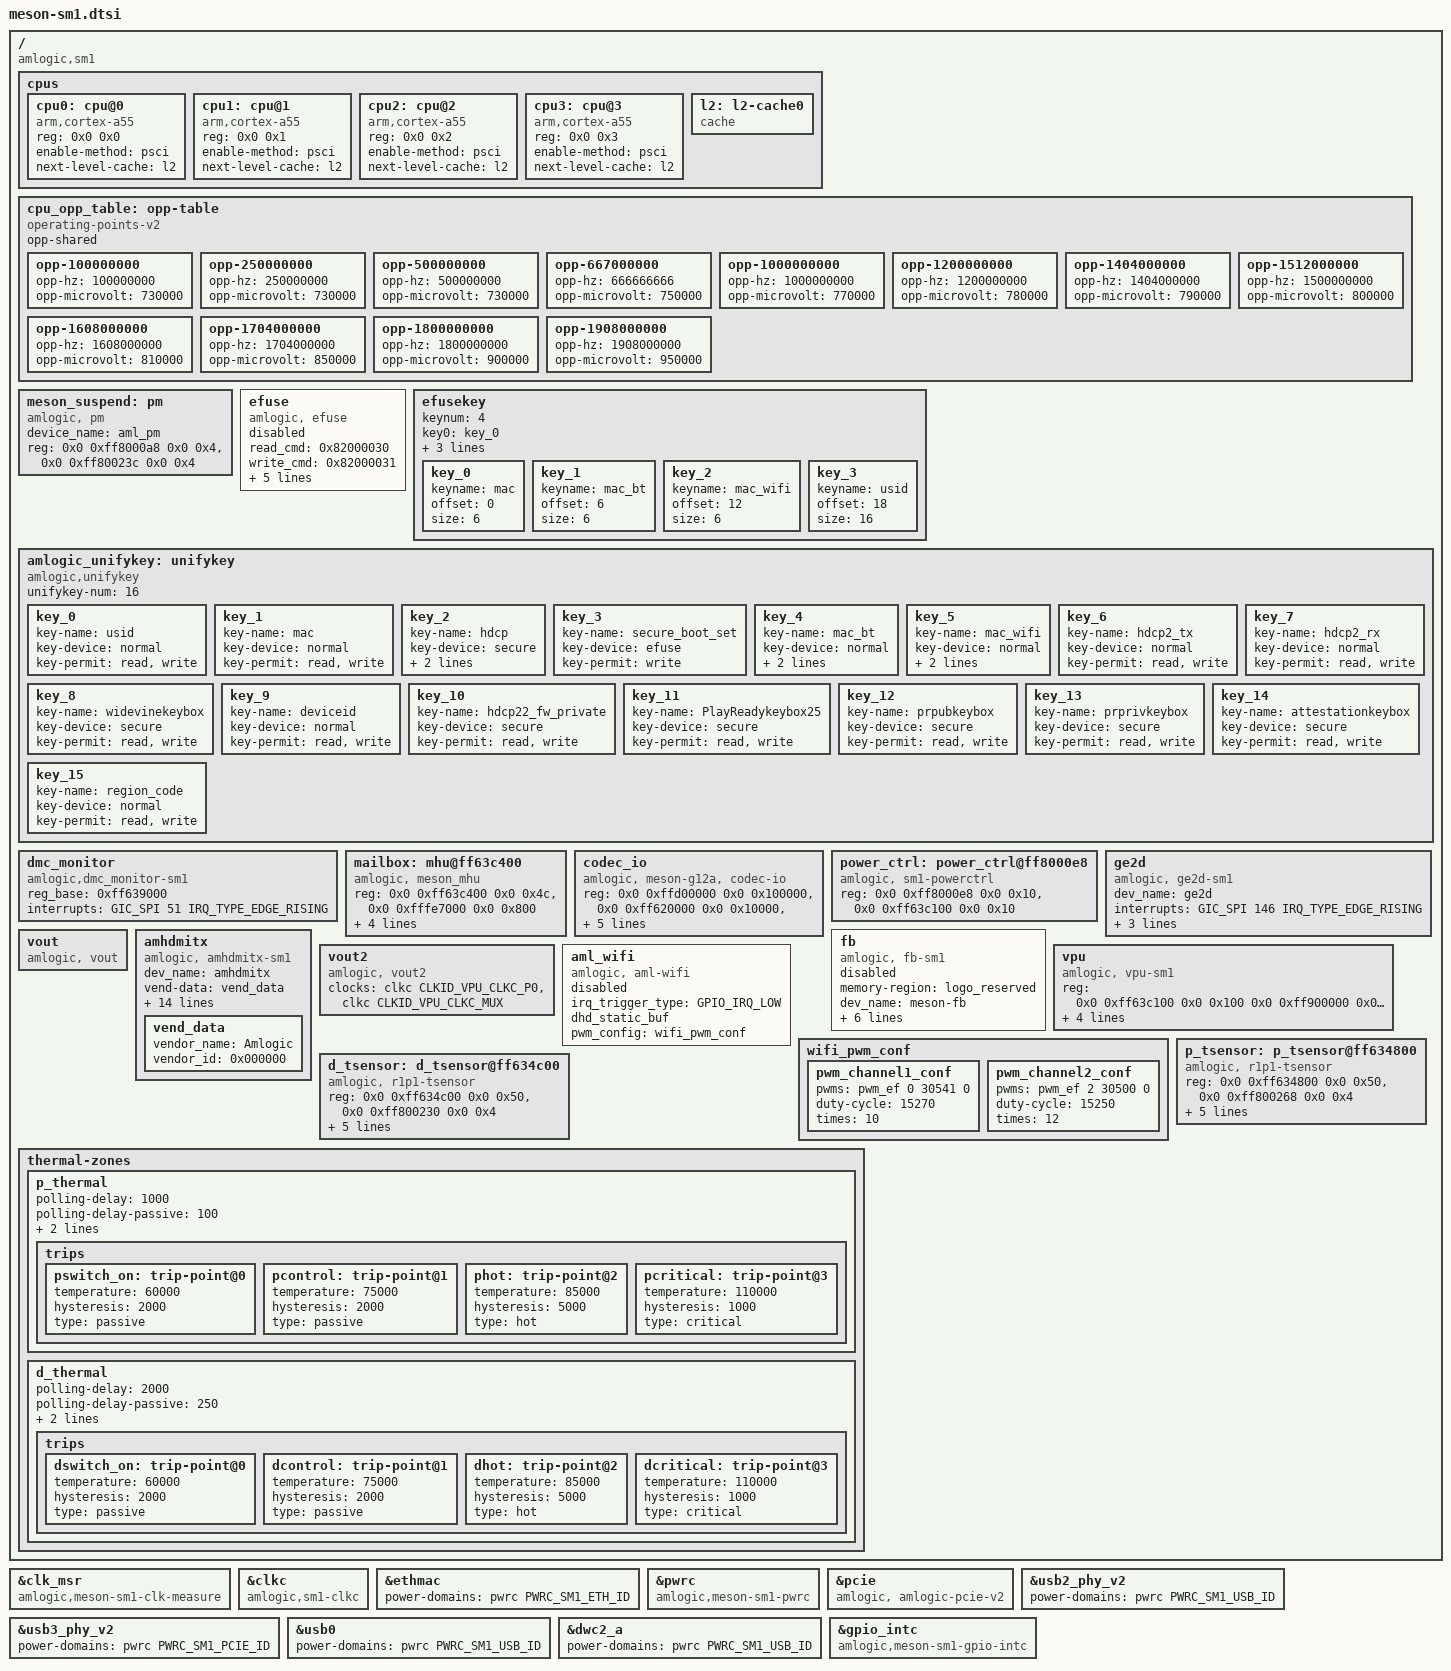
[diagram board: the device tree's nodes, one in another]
// SPDX-License-Identifier: (GPL-2.0+ OR MIT)
/*
 * Copyright (c) 2019 BayLibre, SAS
 * Author: Neil Armstrong <narmstrong@baylibre.com>
 */

#include "meson-g12-common.dtsi"
#include <dt-bindings/power/meson-sm1-power.h>

/ {
	compatible = "amlogic,sm1";

	cpus {
		#address-cells = <0x2>;
		#size-cells = <0x0>;

		cpu0: cpu@0 {
			device_type = "cpu";
			compatible = "arm,cortex-a55";
			reg = <0x0 0x0>;
			enable-method = "psci";
			next-level-cache = <&l2>;
		};

		cpu1: cpu@1 {
			device_type = "cpu";
			compatible = "arm,cortex-a55";
			reg = <0x0 0x1>;
			enable-method = "psci";
			next-level-cache = <&l2>;
		};

		cpu2: cpu@2 {
			device_type = "cpu";
			compatible = "arm,cortex-a55";
			reg = <0x0 0x2>;
			enable-method = "psci";
			next-level-cache = <&l2>;
		};

		cpu3: cpu@3 {
			device_type = "cpu";
			compatible = "arm,cortex-a55";
			reg = <0x0 0x3>;
			enable-method = "psci";
			next-level-cache = <&l2>;
		};

		l2: l2-cache0 {
			compatible = "cache";
		};
	};

	cpu_opp_table: opp-table {
		compatible = "operating-points-v2";
		opp-shared;

		opp-100000000 {
			opp-hz = /bits/ 64 <100000000>;
			opp-microvolt = <730000>;
		};

		opp-250000000 {
			opp-hz = /bits/ 64 <250000000>;
			opp-microvolt = <730000>;
		};

		opp-500000000 {
			opp-hz = /bits/ 64 <500000000>;
			opp-microvolt = <730000>;
		};

		opp-667000000 {
			opp-hz = /bits/ 64 <666666666>;
			opp-microvolt = <750000>;
		};

		opp-1000000000 {
			opp-hz = /bits/ 64 <1000000000>;
			opp-microvolt = <770000>;
		};

		opp-1200000000 {
			opp-hz = /bits/ 64 <1200000000>;
			opp-microvolt = <780000>;
		};

		opp-1404000000 {
			opp-hz = /bits/ 64 <1404000000>;
			opp-microvolt = <790000>;
		};

		opp-1512000000 {
			opp-hz = /bits/ 64 <1500000000>;
			opp-microvolt = <800000>;
		};

		opp-1608000000 {
			opp-hz = /bits/ 64 <1608000000>;
			opp-microvolt = <810000>;
		};

		opp-1704000000 {
			opp-hz = /bits/ 64 <1704000000>;
			opp-microvolt = <850000>;
		};

		opp-1800000000 {
			opp-hz = /bits/ 64 <1800000000>;
			opp-microvolt = <900000>;
		};

		opp-1908000000 {
			opp-hz = /bits/ 64 <1908000000>;
			opp-microvolt = <950000>;
		};
	};

	meson_suspend:pm {
		compatible = "amlogic, pm";
		status = "okay";
		device_name = "aml_pm";
		reg = <0x0 0xff8000a8 0x0 0x4>,
			<0x0 0xff80023c 0x0 0x4>;
	};

	efuse: efuse {
		compatible = "amlogic, efuse";
		read_cmd = <0x82000030>;
		write_cmd = <0x82000031>;
		get_max_cmd = <0x82000033>;
		mem_in_base_cmd = <0x82000020>;
		mem_out_base_cmd = <0x82000021>;
		key = <&efusekey>;
		clocks = <&clkc CLKID_EFUSE>;
		clock-names = "efuse_clk";
		status = "disabled";
	};

	efusekey: efusekey {
		keynum = <4>;
		key0 = <&key_0>;
		key1 = <&key_1>;
		key2 = <&key_2>;
		key3 = <&key_3>;

		key_0: key_0 {
			keyname = "mac";
			offset = <0>;
			size = <6>;
		};
		key_1: key_1 {
			keyname = "mac_bt";
			offset = <6>;
			size = <6>;
		};
		key_2: key_2 {
			keyname = "mac_wifi";
			offset = <12>;
			size = <6>;
		};
		key_3: key_3 {
			keyname = "usid";
			offset = <18>;
			size = <16>;
		};
	};

	amlogic_unifykey: unifykey{
		compatible = "amlogic,unifykey";
		status = "okay";

		unifykey-num = <16>;

		key_0{
			key-name = "usid";
			key-device = "normal";
			key-permit = "read","write";
		};
		key_1{
			key-name = "mac";
			key-device = "normal";
			key-permit = "read","write";
		};
		key_2{
			key-name = "hdcp";
			key-device = "secure";
			key-type = "sha1";
			key-permit = "read","write";
		};
		key_3{
			key-name = "secure_boot_set";
			key-device = "efuse";
			key-permit = "write";
		};
		key_4{
			key-name = "mac_bt";
			key-device = "normal";
			key-permit = "read","write";
			key-type  = "mac";
		};
		key_5{
			key-name = "mac_wifi";
			key-device = "normal";
			key-permit = "read","write";
			key-type = "mac";
		};
		key_6{
			key-name = "hdcp2_tx";
			key-device = "normal";
			key-permit = "read","write";
		};
		key_7{
			key-name = "hdcp2_rx";
			key-device = "normal";
			key-permit = "read","write";
		};
		key_8{
			key-name = "widevinekeybox";
			key-device = "secure";
			key-permit = "read","write";
		};
		key_9{
			key-name = "deviceid";
			key-device = "normal";
			key-permit = "read","write";
		};
		key_10{
			key-name = "hdcp22_fw_private";
			key-device = "secure";
			key-permit = "read","write";
		};
		key_11{
			key-name = "PlayReadykeybox25";
			key-device = "secure";
			key-permit = "read","write";
		};
		key_12{
			key-name = "prpubkeybox";// PlayReady
			key-device = "secure";
			key-permit = "read","write";
		};
		key_13{
			key-name = "prprivkeybox";// PlayReady
			key-device = "secure";
			key-permit = "read","write";
		};
		key_14{
			key-name = "attestationkeybox";// attestation key
			key-device = "secure";
			key-permit = "read","write";
		};
		key_15{
			key-name = "region_code";
			key-device = "normal";
			key-permit = "read","write";
		};
	};//End unifykey

	dmc_monitor {
		compatible = "amlogic,dmc_monitor-sm1";
		status = "okay";
		reg_base = <0xff639000>;
		interrupts = <GIC_SPI 51 IRQ_TYPE_EDGE_RISING>;
	};

	mailbox: mhu@ff63c400 {
		compatible = "amlogic, meson_mhu";
		reg = <0x0 0xff63c400 0x0 0x4c>,   /*MHU registers*/
			<0x0 0xfffe7000 0x0 0x800>;   /*Payload area*/
		interrupts = <GIC_SPI 209 IRQ_TYPE_EDGE_RISING>,   /*low isr*/
				<GIC_SPI 210 IRQ_TYPE_EDGE_RISING>; /*high isr*/
		#mbox-cells = <1>;
		mbox-names = "cpu_to_scp_low", "cpu_to_scp_high";
		mboxes = <&mailbox 0 &mailbox 1>;
	};

	codec_io: codec_io {
		compatible = "amlogic, meson-g12a, codec-io";
		status = "okay";
		#address-cells=<2>;
		#size-cells=<2>;
		ranges;
		reg =	<0x0 0xffd00000 0x0 0x100000>,
			<0x0 0xff620000 0x0 0x10000>,
			<0x0 0xff63c000 0x0 0x2000>,
			<0x0 0xff800000 0x0 0x10000>,
			<0x0 0xff900000 0x0 0x40000>,
			<0x0 0xff638000 0x0 0x2000>,
			<0x0 0xff630000 0x0 0x2000>;
		reg-names = "cbus",
			    "dosbus",
			    "hiubus",
			    "aobus",
			    "vcbus",
			    "dmcbus",
			    "efusebus";
	};
	power_ctrl: power_ctrl@ff8000e8 {
		compatible = "amlogic, sm1-powerctrl";
		reg = <0x0 0xff8000e8 0x0 0x10>,
		<0x0 0xff63c100 0x0 0x10>;
	};

	ge2d {
		compatible = "amlogic, ge2d-sm1";
		dev_name = "ge2d";
		status = "okay";
		interrupts = <GIC_SPI 146 IRQ_TYPE_EDGE_RISING>;
		interrupt-names = "ge2d";
		clocks = <&clkc CLKID_VAPB_SEL>,
			<&clkc CLKID_G2D>,
			<&clkc CLKID_VAPB>;
		clock-names = "clk_vapb_0",
			"clk_ge2d",
			"clk_ge2d_gate";
		reg = <0x0 0xff940000 0x0 0x10000>;
	};

	vout {
		compatible = "amlogic, vout";
		status = "okay";
	};

	fb: fb {
		compatible = "amlogic, fb-sm1";
		memory-region = <&logo_reserved>;
		dev_name = "meson-fb";
		status = "disable";
		interrupts = <GIC_SPI 3 IRQ_TYPE_EDGE_RISING
			GIC_SPI 56 IRQ_TYPE_EDGE_RISING
			GIC_SPI 89 IRQ_TYPE_EDGE_RISING>;
		interrupt-names = "viu-vsync", "viu2-vsync", "rdma";
		/* uboot logo,fb0/fb1 memory size,if afbcd fb0=0x01851000*/
		display_mode_default = "1080p60hz";
		scale_mode = <1>;
		/** 0:VPU free scale 1:OSD free scale 2:OSD super scale */
		display_size_default = <1920 1080 1920 2160 32>;
		/*1920*1080*4*3 = 0x17BB000*/
		clocks = <&clkc CLKID_VPU_CLKC_MUX>;
		clock-names = "vpu_clkc";
	};

	amhdmitx: amhdmitx{
		compatible = "amlogic, amhdmitx-sm1";
		dev_name = "amhdmitx";
		status = "okay";
		vend-data = <&vend_data>;
		pinctrl-names="default", "hdmitx_i2c";
		pinctrl-0=<&hdmitx_hpd_pins &hdmitx_ddc_pins>;
		pinctrl-1=<&hdmitx_hpd_gpio &i2c3_sda_h_pins>;
		clocks = <&clkc CLKID_VCLK2_ENCI
			&clkc CLKID_VCLK2_VENCI0
			&clkc CLKID_VCLK2_VENCI1
			&clkc CLKID_VAPB_SEL
			&clkc CLKID_VPU>;
		clock-names = "venci_top_gate",
			"venci_0_gate",
			"venci_1_gate",
			"hdmi_vapb_clk",
			"hdmi_vpu_clk";
		/* HPD, 57 + 32 = 89; CEC, 151 + 32 = 183*/
		interrupts = <GIC_SPI 57 IRQ_TYPE_EDGE_RISING>;
		interrupt-names = "hdmitx_hpd";
		/* 0:M8B 1:GXBB 2:GXTVBB 3:GXL 4:GXM
		 * 5:TXL 6:TXLX 7:AXG 8:GXLX 9:TXHD
		 * 10:G12A 11:G12B 12:SM1
		 */
		ic_type = <12>;
		reg =	<0x0 0xffd00000 0x0 0x100000>,
			<0x0 0xff900000 0x0 0x40000>,
			<0x0 0xff63c000 0x0 0x2000>,
			<0x0 0xff600000 0x0 0x8000>,
			<0x0 0xff608000 0x0 0x4000>,
			<0x0 0xffe01000 0x0 0x100>;
		reg-names = "cbus",
			    "vcbus",
			    "hiubus",
			    "hdmitxsec",
			    "hdmitx",
			    "esm";

		vend_data: vend_data{ /* Should modified by Customer */
			vendor_name = "Amlogic"; /* Max Chars: 8 */
			/* standards.ieee.org/develop/regauth/oui/oui.txt */
			vendor_id = <0x000000>;
		};
	};

	vout2 {
		compatible = "amlogic, vout2";
		status = "okay";
		clocks = <&clkc CLKID_VPU_CLKC_P0>,
			<&clkc CLKID_VPU_CLKC_MUX>;
		clock-names = "vpu_clkc0",
			"vpu_clkc";
	};
	vpu: vpu {
		compatible = "amlogic, vpu-sm1";
		status = "okay";
		reg =	<0x0 0xff63c100 0x0 0x100    /* hiu */
			0x0 0xff900000 0x0 0x50000 /* vcbus */
			0x0 0xffd01080 0x0 0x20    /* cbus */
			0x0 0xff8000e8 0x0 0x2>;   /* aobus */
		clocks = <&clkc CLKID_VAPB_SEL>,
			<&clkc CLKID_VPU_INTR>,
			<&clkc CLKID_VPU_0>,
			<&clkc CLKID_VPU_1>,
			<&clkc CLKID_VPU>;
		clock-names =	"vapb_clk",
				"vpu_intr_gate",
				"vpu_clk0",
				"vpu_clk1",
				"vpu_clk";
		clk_level = <7>;
		/* 0: 100.0M    1: 166.7M    2: 200.0M    3: 250.0M */
		/* 4: 333.3M    5: 400.0M    6: 500.0M    7: 666.7M */
	};

	aml_wifi: aml_wifi {
		compatible = "amlogic, aml-wifi";
		status = "disabled";
		irq_trigger_type = "GPIO_IRQ_LOW";
		dhd_static_buf; //if use bcm wifi, config dhd_static_buf
		//pinctrl-0 = <&pwm_e_pins>;
		//pinctrl-names = "default";
		pwm_config = <&wifi_pwm_conf>;
	};

	wifi_pwm_conf:wifi_pwm_conf{
		pwm_channel1_conf {
			pwms = <&pwm_ef 0 30541 0>;
			duty-cycle = <15270>;
			times = <10>;
		};
		pwm_channel2_conf {
			pwms = <&pwm_ef 2 30500 0>;
			duty-cycle = <15250>;
			times = <12>;
		};
	};

	p_tsensor: p_tsensor@ff634800 {
		compatible = "amlogic, r1p1-tsensor";
		status = "okay";
		reg = <0x0 0xff634800 0x0 0x50>,
			<0x0 0xff800268 0x0 0x4>;
		cal_type = <0x1>;
		cal_coeff = <324 424 3159 9411>;
		rtemp = <115000>;
		interrupts = <GIC_SPI 35 IRQ_TYPE_LEVEL_HIGH>;
		clocks = <&clkc CLKID_TS>; /* CLKID_TS_COMP>;*/
		clock-names = "ts_comp";
		#thermal-sensor-cells = <1>;
	};

	d_tsensor: d_tsensor@ff634c00 {
		compatible = "amlogic, r1p1-tsensor";
		status = "okay";
		reg = <0x0 0xff634c00 0x0 0x50>,
			<0x0 0xff800230 0x0 0x4>;
		cal_type = <0x1>;
		cal_coeff = <324 424 3159 9411>;
		rtemp = <115000>;
		interrupts = <GIC_SPI 36 IRQ_TYPE_LEVEL_HIGH>;
		clocks = <&clkc CLKID_TS>; /* CLKID_TS_COMP>;*/
		clock-names = "ts_comp";
		#thermal-sensor-cells = <1>;
	};

	thermal-zones {
		p_thermal: p_thermal {
			polling-delay = <1000>;
			polling-delay-passive = <100>;
			sustainable-power = <1460>;
			thermal-sensors = <&p_tsensor 0>;
			trips {
				pswitch_on: trip-point@0 {
					temperature = <60000>;
					hysteresis = <2000>;
					type = "passive";
				};
				pcontrol: trip-point@1 {
					temperature = <75000>;
					hysteresis = <2000>;
					type = "passive";
				};
				phot: trip-point@2 {
					temperature = <85000>;
					hysteresis = <5000>;
					type = "hot";
				};
				pcritical: trip-point@3 {
					temperature = <110000>;
					hysteresis = <1000>;
					type = "critical";
				};
			};
		};

		d_thermal: d_thermal {
			polling-delay = <2000>;
			polling-delay-passive = <250>;
			sustainable-power = <1460>;
			thermal-sensors = <&d_tsensor 1>;
			trips {
				dswitch_on: trip-point@0 {
					temperature = <60000>;
					hysteresis = <2000>;
					type = "passive";
				};
				dcontrol: trip-point@1 {
					temperature = <75000>;
					hysteresis = <2000>;
					type = "passive";
				};
				dhot: trip-point@2 {
					temperature = <85000>;
					hysteresis = <5000>;
					type = "hot";
				};
				dcritical: trip-point@3 {
					temperature = <110000>;
					hysteresis = <1000>;
					type = "critical";
				};
			};
		};
	};
};

/*
&cecb_AO {
	compatible = "amlogic,meson-sm1-ao-cec";
};
*/

&clk_msr {
	compatible = "amlogic,meson-sm1-clk-measure";
};


&clkc {
	compatible = "amlogic,sm1-clkc";
};

&ethmac {
	power-domains = <&pwrc PWRC_SM1_ETH_ID>;
};

&pwrc {
	compatible = "amlogic,meson-sm1-pwrc";
};

/*
&vpu {
	power-domains = <&pwrc PWRC_SM1_VPU_ID>;
};
*/
&pcie {
	compatible = "amlogic, amlogic-pcie-v2";
};

&usb2_phy_v2 {
	power-domains = <&pwrc PWRC_SM1_USB_ID>;
};

&usb3_phy_v2 {
	power-domains = <&pwrc PWRC_SM1_PCIE_ID>;
};

&usb0 {
	power-domains = <&pwrc PWRC_SM1_USB_ID>;
};

&dwc2_a {
	power-domains = <&pwrc PWRC_SM1_USB_ID>;
};

&gpio_intc {
	compatible = "amlogic,meson-sm1-gpio-intc",
		     "amlogic,meson-gpio-intc";
};
